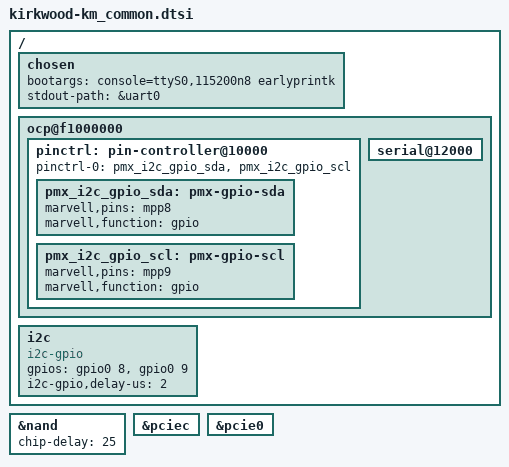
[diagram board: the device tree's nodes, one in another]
// SPDX-License-Identifier: GPL-2.0
/ {
	chosen {
		bootargs = "console=ttyS0,115200n8 earlyprintk";
		stdout-path = &uart0;
	};

	ocp@f1000000 {
		pinctrl: pin-controller@10000 {
			pinctrl-0 = < &pmx_i2c_gpio_sda &pmx_i2c_gpio_scl >;
			pinctrl-names = "default";

			pmx_i2c_gpio_sda: pmx-gpio-sda {
				marvell,pins = "mpp8";
				marvell,function = "gpio";
			};
			pmx_i2c_gpio_scl: pmx-gpio-scl {
				marvell,pins = "mpp9";
				marvell,function = "gpio";
			};
		};

		serial@12000 {
			status = "okay";
		};
	};

	i2c {
		compatible = "i2c-gpio";
		gpios = < &gpio0 8 GPIO_ACTIVE_HIGH		/* sda */
			  &gpio0 9 GPIO_ACTIVE_HIGH>;		/* scl */
		i2c-gpio,delay-us = <2>;	/* ~100 kHz */
	};
};

&nand {
	status = "okay";
	chip-delay = <25>;
};

&pciec {
        status = "okay";
};

&pcie0 {
	status = "okay";
};
